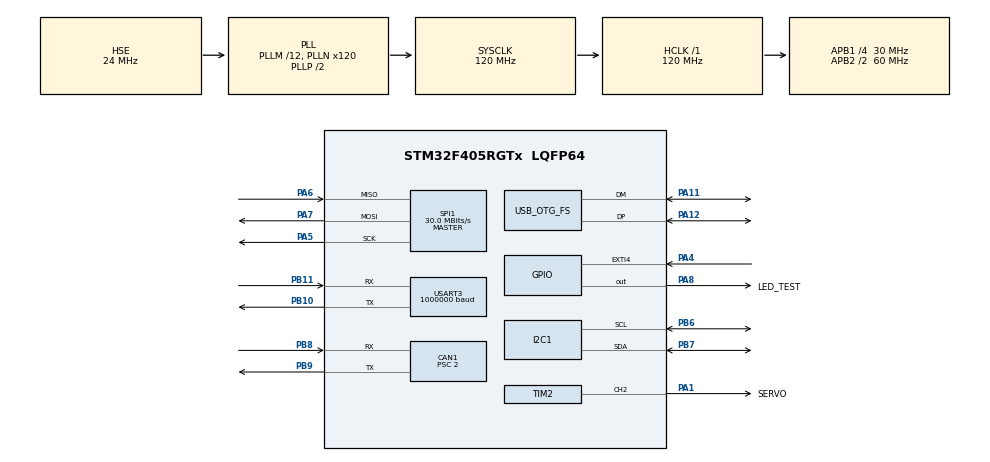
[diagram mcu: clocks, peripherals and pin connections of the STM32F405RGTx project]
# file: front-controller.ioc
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CAN1.BS1=CAN_BS1_12TQ
CAN1.BS2=CAN_BS2_2TQ
CAN1.CalculateBaudRate=999999
CAN1.CalculateTimeBit=1000
CAN1.CalculateTimeQuantum=66.66666666666667
CAN1.Mode=CAN_MODE_NORMAL
CAN1.Prescaler=2
Mcu.Family=STM32F4
Mcu.Name=STM32F405RGTx
Mcu.Package=LQFP64
NVIC.CAN1_RX0_IRQn=true\:0\:0\:false\:false\:true\:true\:true\:true
NVIC.EXTI4_IRQn=true\:0\:0\:false\:false\:true\:true\:true\:true
NVIC.PriorityGroup=NVIC_PRIORITYGROUP_4
PA1.GPIO_Label=SERVO
PA1.Signal=S_TIM2_CH2
PA11.Mode=Device_Only
PA11.Signal=USB_OTG_FS_DM
PA12.Mode=Device_Only
PA12.Signal=USB_OTG_FS_DP
PA13.Mode=Trace_Asynchronous_SW
PA13.Signal=SYS_JTMS-SWDIO
PA14.Mode=Trace_Asynchronous_SW
PA14.Signal=SYS_JTCK-SWCLK
PA4.Signal=GPXTI4
PA5.Mode=Full_Duplex_Master
PA5.Signal=SPI1_SCK
PA6.Mode=Full_Duplex_Master
PA6.Signal=SPI1_MISO
PA7.Mode=Full_Duplex_Master
PA7.Signal=SPI1_MOSI
PA8.GPIO_Label=LED_TEST
PA8.Signal=GPIO_Output
PB10.Mode=Asynchronous
PB10.Signal=USART3_TX
PB11.Mode=Asynchronous
PB11.Signal=USART3_RX
PB3.Mode=Trace_Asynchronous_SW
PB3.Signal=SYS_JTDO-SWO
PB6.Mode=I2C
PB6.Signal=I2C1_SCL
PB7.Mode=I2C
PB7.Signal=I2C1_SDA
PB8.Mode=CAN_Activate
PB8.Signal=CAN1_RX
PB9.Mode=CAN_Activate
PB9.Signal=CAN1_TX
PH0-OSC_IN.Mode=HSE-External-Oscillator
PH0-OSC_IN.Signal=RCC_OSC_IN
PH1-OSC_OUT.Mode=HSE-External-Oscillator
PH1-OSC_OUT.Signal=RCC_OSC_OUT
ProjectManager.HeapSize=0x200
ProjectManager.StackSize=0x400
ProjectManager.TargetToolchain=STM32CubeIDE
RCC.48MHZClocksFreq_Value=48000000
RCC.AHBFreq_Value=120000000
RCC.APB1CLKDivider=RCC_HCLK_DIV4
RCC.APB1Freq_Value=30000000
RCC.APB1TimFreq_Value=60000000
RCC.APB2CLKDivider=RCC_HCLK_DIV2
RCC.APB2Freq_Value=60000000
RCC.APB2TimFreq_Value=120000000
RCC.CortexFreq_Value=120000000
RCC.HCLKFreq_Value=120000000
RCC.HSE_VALUE=24000000
RCC.HSI_VALUE=16000000
RCC.LSE_VALUE=32768
RCC.PLLM=12
RCC.PLLN=120
RCC.PLLQ=5
RCC.SYSCLKFreq_VALUE=120000000
RCC.SYSCLKSource=RCC_SYSCLKSOURCE_PLLCLK
RCC.VCOOutputFreq_Value=240000000
SH.S_TIM2_CH2.0=TIM2_CH2,PWM Generation2 CH2
SPI1.CalculateBaudRate=30.0 MBits/s
SPI1.Direction=SPI_DIRECTION_2LINES
SPI1.Mode=SPI_MODE_MASTER
SPI1.VirtualType=VM_MASTER
TIM2.Channel-PWM\ Generation2\ CH2=TIM_CHANNEL_2
USART3.BaudRate=1000000
USART3.VirtualMode=VM_ASYNC
USB_OTG_FS.VirtualMode=Device_Only
VP_TIM2_VS_ClockSourceINT.Mode=Internal
board=custom

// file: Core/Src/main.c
/* USER CODE BEGIN Header */
/**
  ******************************************************************************
  * @file           : main.c
  * @brief          : Main program body
  ******************************************************************************
  * @attention
  *
  * Copyright (c) 2024 STMicroelectronics.
  * All rights reserved.
  *
  * This software is licensed under terms that can be found in the LICENSE file
  * in the root directory of this software component.
  * If no LICENSE file comes with this software, it is provided AS-IS.
  *
  ******************************************************************************
  */
/* USER CODE END Header */
#include "main.h"

CAN_HandleTypeDef hcan1;

I2C_HandleTypeDef hi2c1;

SPI_HandleTypeDef hspi1;

TIM_HandleTypeDef htim2;

UART_HandleTypeDef huart3;

PCD_HandleTypeDef hpcd_USB_OTG_FS;

void SystemClock_Config(void);
static void MX_GPIO_Init(void);
static void MX_CAN1_Init(void);
static void MX_I2C1_Init(void);
static void MX_SPI1_Init(void);
static void MX_USART3_UART_Init(void);
static void MX_USB_OTG_FS_PCD_Init(void);
static void MX_TIM2_Init(void);

int main(void)
{

  /* MCU Configuration--------------------------------------------------------*/

  /* Reset of all peripherals, Initializes the Flash interface and the Systick. */
  HAL_Init();

  /* Configure the system clock */
  SystemClock_Config();

  /* Initialize all configured peripherals */
  MX_GPIO_Init();
  MX_CAN1_Init();
  MX_I2C1_Init();
  MX_SPI1_Init();
  MX_USART3_UART_Init();
  MX_USB_OTG_FS_PCD_Init();
  MX_TIM2_Init();

  /* Infinite loop */
  /* USER CODE BEGIN WHILE */
  while (1)
  {
	  HAL_GPIO_TogglePin(LED_TEST_GPIO_Port, LED_TEST_Pin);
	  HAL_Delay(500);
    /* USER CODE END WHILE */

  }
}

void SystemClock_Config(void)
{
  RCC_OscInitTypeDef RCC_OscInitStruct = {0};
  RCC_ClkInitTypeDef RCC_ClkInitStruct = {0};

  /** Configure the main internal regulator output voltage
  */
  __HAL_RCC_PWR_CLK_ENABLE();
  __HAL_PWR_VOLTAGESCALING_CONFIG(PWR_REGULATOR_VOLTAGE_SCALE1);

  /** Initializes the RCC Oscillators according to the specified parameters
  * in the RCC_OscInitTypeDef structure.
  */
  RCC_OscInitStruct.OscillatorType = RCC_OSCILLATORTYPE_HSE;
  RCC_OscInitStruct.HSEState = RCC_HSE_ON;
  RCC_OscInitStruct.PLL.PLLState = RCC_PLL_ON;
  RCC_OscInitStruct.PLL.PLLSource = RCC_PLLSOURCE_HSE;
  RCC_OscInitStruct.PLL.PLLM = 12;
  RCC_OscInitStruct.PLL.PLLN = 120;
  RCC_OscInitStruct.PLL.PLLP = RCC_PLLP_DIV2;
  RCC_OscInitStruct.PLL.PLLQ = 5;
  if (HAL_RCC_OscConfig(&RCC_OscInitStruct) != HAL_OK)
  {
    Error_Handler();
  }

  /** Initializes the CPU, AHB and APB buses clocks
  */
  RCC_ClkInitStruct.ClockType = RCC_CLOCKTYPE_HCLK|RCC_CLOCKTYPE_SYSCLK
                              |RCC_CLOCKTYPE_PCLK1|RCC_CLOCKTYPE_PCLK2;
  RCC_ClkInitStruct.SYSCLKSource = RCC_SYSCLKSOURCE_PLLCLK;
  RCC_ClkInitStruct.AHBCLKDivider = RCC_SYSCLK_DIV1;
  RCC_ClkInitStruct.APB1CLKDivider = RCC_HCLK_DIV4;
  RCC_ClkInitStruct.APB2CLKDivider = RCC_HCLK_DIV2;

  if (HAL_RCC_ClockConfig(&RCC_ClkInitStruct, FLASH_LATENCY_3) != HAL_OK)
  {
    Error_Handler();
  }
}

static void MX_CAN1_Init(void)
{

  hcan1.Instance = CAN1;
  hcan1.Init.Prescaler = 2;
  hcan1.Init.Mode = CAN_MODE_NORMAL;
  hcan1.Init.SyncJumpWidth = CAN_SJW_1TQ;
  hcan1.Init.TimeSeg1 = CAN_BS1_12TQ;
  hcan1.Init.TimeSeg2 = CAN_BS2_2TQ;
  hcan1.Init.TimeTriggeredMode = DISABLE;
  hcan1.Init.AutoBusOff = DISABLE;
  hcan1.Init.AutoWakeUp = DISABLE;
  hcan1.Init.AutoRetransmission = DISABLE;
  hcan1.Init.ReceiveFifoLocked = DISABLE;
  hcan1.Init.TransmitFifoPriority = DISABLE;
  if (HAL_CAN_Init(&hcan1) != HAL_OK)
  {
    Error_Handler();
  }

}

static void MX_I2C1_Init(void)
{

  hi2c1.Instance = I2C1;
  hi2c1.Init.ClockSpeed = 100000;
  hi2c1.Init.DutyCycle = I2C_DUTYCYCLE_2;
  hi2c1.Init.OwnAddress1 = 0;
  hi2c1.Init.AddressingMode = I2C_ADDRESSINGMODE_7BIT;
  hi2c1.Init.DualAddressMode = I2C_DUALADDRESS_DISABLE;
  hi2c1.Init.OwnAddress2 = 0;
  hi2c1.Init.GeneralCallMode = I2C_GENERALCALL_DISABLE;
  hi2c1.Init.NoStretchMode = I2C_NOSTRETCH_DISABLE;
  if (HAL_I2C_Init(&hi2c1) != HAL_OK)
  {
    Error_Handler();
  }

}

static void MX_SPI1_Init(void)
{

  /* SPI1 parameter configuration*/
  hspi1.Instance = SPI1;
  hspi1.Init.Mode = SPI_MODE_MASTER;
  hspi1.Init.Direction = SPI_DIRECTION_2LINES;
  hspi1.Init.DataSize = SPI_DATASIZE_8BIT;
  hspi1.Init.CLKPolarity = SPI_POLARITY_LOW;
  hspi1.Init.CLKPhase = SPI_PHASE_1EDGE;
  hspi1.Init.NSS = SPI_NSS_SOFT;
  hspi1.Init.BaudRatePrescaler = SPI_BAUDRATEPRESCALER_2;
  hspi1.Init.FirstBit = SPI_FIRSTBIT_MSB;
  hspi1.Init.TIMode = SPI_TIMODE_DISABLE;
  hspi1.Init.CRCCalculation = SPI_CRCCALCULATION_DISABLE;
  hspi1.Init.CRCPolynomial = 10;
  if (HAL_SPI_Init(&hspi1) != HAL_OK)
  {
    Error_Handler();
  }

}

static void MX_TIM2_Init(void)
{

  TIM_ClockConfigTypeDef sClockSourceConfig = {0};
  TIM_MasterConfigTypeDef sMasterConfig = {0};
  TIM_OC_InitTypeDef sConfigOC = {0};

  htim2.Instance = TIM2;
  htim2.Init.Prescaler = 0;
  htim2.Init.CounterMode = TIM_COUNTERMODE_UP;
  htim2.Init.Period = 4294967295;
  htim2.Init.ClockDivision = TIM_CLOCKDIVISION_DIV1;
  htim2.Init.AutoReloadPreload = TIM_AUTORELOAD_PRELOAD_DISABLE;
  if (HAL_TIM_Base_Init(&htim2) != HAL_OK)
  {
    Error_Handler();
  }
  sClockSourceConfig.ClockSource = TIM_CLOCKSOURCE_INTERNAL;
  if (HAL_TIM_ConfigClockSource(&htim2, &sClockSourceConfig) != HAL_OK)
  {
    Error_Handler();
  }
  if (HAL_TIM_PWM_Init(&htim2) != HAL_OK)
  {
    Error_Handler();
  }
  sMasterConfig.MasterOutputTrigger = TIM_TRGO_RESET;
  sMasterConfig.MasterSlaveMode = TIM_MASTERSLAVEMODE_DISABLE;
  if (HAL_TIMEx_MasterConfigSynchronization(&htim2, &sMasterConfig) != HAL_OK)
  {
    Error_Handler();
  }
  sConfigOC.OCMode = TIM_OCMODE_PWM1;
  sConfigOC.Pulse = 0;
  sConfigOC.OCPolarity = TIM_OCPOLARITY_HIGH;
  sConfigOC.OCFastMode = TIM_OCFAST_DISABLE;
  if (HAL_TIM_PWM_ConfigChannel(&htim2, &sConfigOC, TIM_CHANNEL_2) != HAL_OK)
  {
    Error_Handler();
  }
  HAL_TIM_MspPostInit(&htim2);

}

static void MX_USART3_UART_Init(void)
{

  huart3.Instance = USART3;
  huart3.Init.BaudRate = 1000000;
  huart3.Init.WordLength = UART_WORDLENGTH_8B;
  huart3.Init.StopBits = UART_STOPBITS_1;
  huart3.Init.Parity = UART_PARITY_NONE;
  huart3.Init.Mode = UART_MODE_TX_RX;
  huart3.Init.HwFlowCtl = UART_HWCONTROL_NONE;
  huart3.Init.OverSampling = UART_OVERSAMPLING_16;
  if (HAL_UART_Init(&huart3) != HAL_OK)
  {
    Error_Handler();
  }

}

static void MX_USB_OTG_FS_PCD_Init(void)
{

  hpcd_USB_OTG_FS.Instance = USB_OTG_FS;
  hpcd_USB_OTG_FS.Init.dev_endpoints = 4;
  hpcd_USB_OTG_FS.Init.speed = PCD_SPEED_FULL;
  hpcd_USB_OTG_FS.Init.dma_enable = DISABLE;
  hpcd_USB_OTG_FS.Init.phy_itface = PCD_PHY_EMBEDDED;
  hpcd_USB_OTG_FS.Init.Sof_enable = DISABLE;
  hpcd_USB_OTG_FS.Init.low_power_enable = DISABLE;
  hpcd_USB_OTG_FS.Init.lpm_enable = DISABLE;
  hpcd_USB_OTG_FS.Init.vbus_sensing_enable = DISABLE;
  hpcd_USB_OTG_FS.Init.use_dedicated_ep1 = DISABLE;
  if (HAL_PCD_Init(&hpcd_USB_OTG_FS) != HAL_OK)
  {
    Error_Handler();
  }

}

static void MX_GPIO_Init(void)
{
  GPIO_InitTypeDef GPIO_InitStruct = {0};

  /* GPIO Ports Clock Enable */
  __HAL_RCC_GPIOH_CLK_ENABLE();
  __HAL_RCC_GPIOA_CLK_ENABLE();
  __HAL_RCC_GPIOB_CLK_ENABLE();

  /*Configure GPIO pin Output Level */
  HAL_GPIO_WritePin(LED_TEST_GPIO_Port, LED_TEST_Pin, GPIO_PIN_RESET);

  /*Configure GPIO pin : PA4 */
  GPIO_InitStruct.Pin = GPIO_PIN_4;
  GPIO_InitStruct.Mode = GPIO_MODE_IT_RISING;
  GPIO_InitStruct.Pull = GPIO_NOPULL;
  HAL_GPIO_Init(GPIOA, &GPIO_InitStruct);

  /*Configure GPIO pin : LED_TEST_Pin */
  GPIO_InitStruct.Pin = LED_TEST_Pin;
  GPIO_InitStruct.Mode = GPIO_MODE_OUTPUT_PP;
  GPIO_InitStruct.Pull = GPIO_NOPULL;
  GPIO_InitStruct.Speed = GPIO_SPEED_FREQ_LOW;
  HAL_GPIO_Init(LED_TEST_GPIO_Port, &GPIO_InitStruct);

  /* EXTI interrupt init*/
  HAL_NVIC_SetPriority(EXTI4_IRQn, 0, 0);
  HAL_NVIC_EnableIRQ(EXTI4_IRQn);

}

void Error_Handler(void)
{
  __disable_irq();
  while (1)
  {
  }
}
